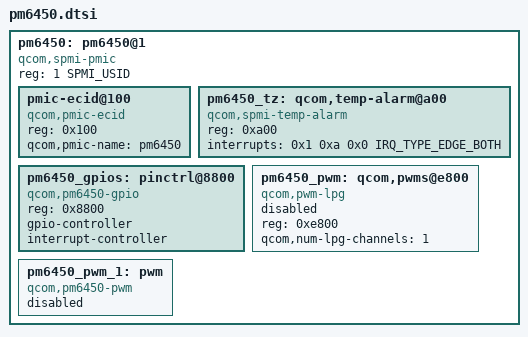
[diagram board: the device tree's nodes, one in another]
// SPDX-License-Identifier: BSD-3-Clause
/*
 * Copyright (c) Qualcomm Technologies, Inc. and/or its subsidiaries.
 */

#include <dt-bindings/interrupt-controller/irq.h>
#include <dt-bindings/leds/common.h>
#include <dt-bindings/spmi/spmi.h>

pm6450: pm6450@1 {
	compatible = "qcom,spmi-pmic";
	reg = <1 SPMI_USID>;
	#address-cells = <1>;
	#size-cells = <0>;

	pmic-ecid@100 {
		compatible = "qcom,pmic-ecid";
		reg = <0x100>;
		qcom,pmic-name = "pm6450";
	};

	pm6450_tz: qcom,temp-alarm@a00 {
		compatible = "qcom,spmi-temp-alarm";
		reg = <0xa00>;
		interrupts = <0x1 0xa 0x0 IRQ_TYPE_EDGE_BOTH>;
		#thermal-sensor-cells = <0>;
	};

	pm6450_gpios: pinctrl@8800 {
		compatible = "qcom,pm6450-gpio";
		reg = <0x8800>;
		gpio-controller;
		#gpio-cells = <2>;
		interrupt-controller;
		#interrupt-cells = <2>;
	};

	pm6450_pwm: qcom,pwms@e800 {
		compatible = "qcom,pwm-lpg";
		reg = <0xe800>;
		reg-names = "lpg-base";
		qcom,num-lpg-channels = <1>;
		#pwm-cells = <2>;
		status = "disabled";
	};

	pm6450_pwm_1: pwm {
		compatible = "qcom,pm6450-pwm";
		#pwm-cells = <2>;
		status = "disabled";
	};
};
